# CY8C4245AXI_483 register map
File version: 0.1
PSoC 4200
Registers are 32-bit, read-write, no defined reset value unless marked. A register's access mark holds for its fields unless they carry their own. Offsets are from the block's base; lines under a group give offsets from that group; [hi:lo] are bit positions; {n}, {i} and the like mark numbered series; 'fields as' and 'values as' point back to an identical list; <NAME> marks a mode.

## Memory map
0x00000000 UART — Serial Communication Block
0x00000000 Timer
0x00000000 Opamp_1 — OpAmp
0x00000000 Opamp_2 — OpAmp
0x00000000 ADC_SAR — Sequencing SAR ADC

## Timer
Base 0x00000000
0x400F0000 Timer_COUNTER 24-bit — UDB.A0 - Current Down Counter Value
0x400F0020 Timer_PERIOD 24-bit — UDB.D0 - Assigned Period
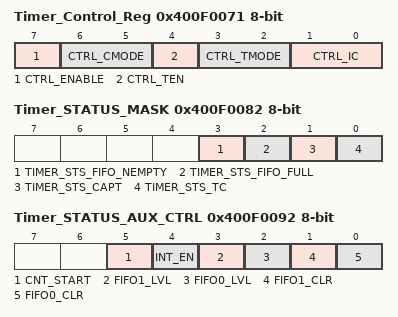
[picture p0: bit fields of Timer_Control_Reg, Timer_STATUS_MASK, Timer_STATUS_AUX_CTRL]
0x400F0071 Timer_Control_Reg 8-bit — UDB Control Register - Assigned Control Register Value
  [7] CTRL_ENABLE — Enable the Timer
  [6:5] CTRL_CMODE — Capture Mode
  [4] CTRL_TEN — Trigger Enable Bit
  [3:2] CTRL_TMODE — Trigger Mode
  [1:0] CTRL_IC — Interrupt Count
0x400F0082 Timer_STATUS_MASK 8-bit — UDB Status bits Interrupt Mask Enable Register
  [3] TIMER_STS_FIFO_NEMPTY ro — FIFO Empty status
  [2] TIMER_STS_FIFO_FULL ro — FIFO Full Status
  [1] TIMER_STS_CAPT ro — Enables the Interrupt on Capture
  [0] TIMER_STS_TC ro — Enables the Interrupt on TC
0x400F0092 Timer_STATUS_AUX_CTRL 8-bit — UDB Auxilliary Control Register
  [5] CNT_START — FIFO0 clear
    0=E_CNT_START0 (Disable counter); 1=E_CNT_START1 (Enable counter)
  [4] INT_EN
    0=E_INT_EN0 (Interrupt disabled); 1=E_INT_EN1 (Interrupt enabled)
  [3] FIFO1_LVL — FIFO level
    0=E_FIFO_LVL_0 (FIFO LVL: input mode: FIFO not full; output mode: FIFO not empty); 1=E_FIFO_LVL_1 (FIFO LVL: input mode: FIFO at least 1/2 empty; output mode: FIFO at least 1/2 full)
  [2] FIFO0_LVL — FIFO level
    values as FIFO1_LVL
  [1] FIFO1_CLR — FIFO1 clear
    0=E_FIFO_CLR_0 (Normal FIFO operation); 1=E_FIFO_CLR_1 (Clear FIFO state)
  [0] FIFO0_CLR — FIFO0 clear
    values as FIFO1_CLR

## Opamp_1 — OpAmp
Base 0x00000000
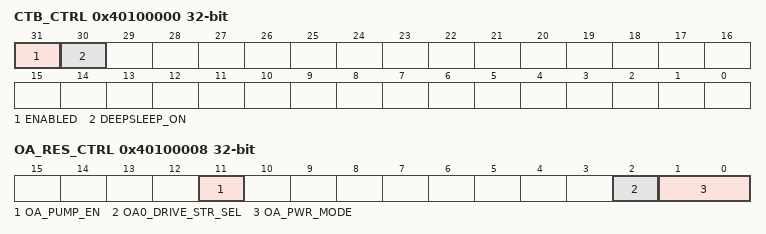
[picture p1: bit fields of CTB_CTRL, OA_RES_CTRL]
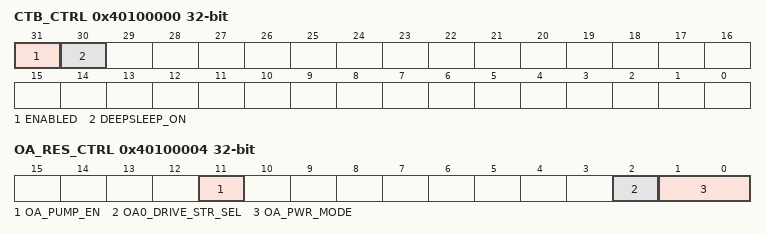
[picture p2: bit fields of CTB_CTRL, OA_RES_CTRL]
0x40100000 CTB_CTRL — Global CTB IP and power control
  [31] ENABLED — Selects component behavior in DeepSleep power mode
    0=DISABLE (CTB IP disabled (put analog in power down, open all switches)); 1=ENABLE (CTB IP enabledCTB IP enabled)
  [30] DEEPSLEEP_ON — Selects component behavior in DeepSleep power mode
    0=DISABLE (CTB IP disabled off during DeepSleep power mode); 1=ENABLE (CTB IP remains enabled during DeepSleep power mode (if ENABLED=1))
0x40100008 OA_RES_CTRL — Opamp and resistor control
  [11] OA_PUMP_EN — Selects pump
    0=DISABLE (Pump disabled); 1=ENABLE (Pump enabled)
  [2] OA0_DRIVE_STR_SEL — Opamp output strenght select
    0=Internal only; 1=Output to pin
  [1:0] OA_PWR_MODE — Selects power for opamp
    0=OFF; 1=LOW (Low power); 2=MED (Medium power); 3=HIGH (High power)
0x40100F14 OA_COMP_TRIM — Opamp Compenation Capacitor Trim
  [1:0] OA_COMP_TRIM
    1=HIGH_SPEED; 2=BALANCED; 3=HIGH_STABILITY

## Opamp_2 — OpAmp
Base 0x00000000
0x40100000 CTB_CTRL — Global CTB IP and power control
  [31] ENABLED — Selects component behavior in DeepSleep power mode
    0=DISABLE (CTB IP disabled (put analog in power down, open all switches)); 1=ENABLE (CTB IP enabledCTB IP enabled)
  [30] DEEPSLEEP_ON — Selects component behavior in DeepSleep power mode
    0=DISABLE (CTB IP disabled off during DeepSleep power mode); 1=ENABLE (CTB IP remains enabled during DeepSleep power mode (if ENABLED=1))
0x40100004 OA_RES_CTRL — Opamp and resistor control
  [11] OA_PUMP_EN — Selects pump
    0=DISABLE (Pump disabled); 1=ENABLE (Pump enabled)
  [2] OA0_DRIVE_STR_SEL — Opamp output strenght select
    0=Internal only; 1=Output to pin
  [1:0] OA_PWR_MODE — Selects power for opamp
    0=OFF; 1=LOW (Low power); 2=MED (Medium power); 3=HIGH (High power)
0x40100F08 OA_COMP_TRIM — Opamp Compenation Capacitor Trim
  [1:0] OA_COMP_TRIM
    1=HIGH_SPEED; 2=BALANCED; 3=HIGH_STABILITY
